# DA1469x register map
Vendor: Dialog; Series: DA1469x; File version: 1.2
CPU: CM33 r1p0, little endian, no MPU, FPU, 3 interrupt priority bits
Registers are 32-bit, read-write, reset 0x0 unless marked. A register's access mark holds for its fields unless they carry their own. Offsets are from the block's base; [hi:lo] are bit positions.

## CRG_SYS — CRG_SYS registers
Base 0x50040500
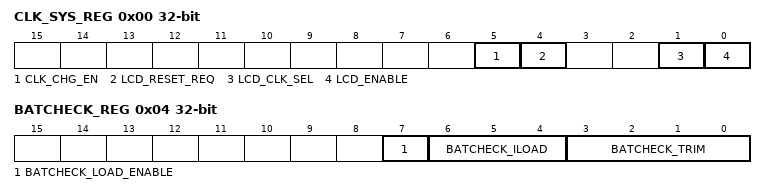
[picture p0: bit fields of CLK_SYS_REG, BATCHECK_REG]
0x00 CLK_SYS_REG — Peripheral divider register
  [5] CLK_CHG_EN — Enables the clocks for the charger FSM block
  [4] LCD_RESET_REQ — Generates a SW reset towards the LCD controller.
  [1] LCD_CLK_SEL — Selects the clock source 1 = DIV1 clock 0 = DIVN clock
  [0] LCD_ENABLE — Enables the clock
0x04 BATCHECK_REG
  [7] BATCHECK_LOAD_ENABLE — Enable a current load on the battery.
  [6:4] BATCHECK_ILOAD — Set the current load to (ILOAD+1) mA.
  [3:0] BATCHECK_TRIM — Trim the current load with steps of 2.7 percent from -19.1 percent to +19.1 percent. 0: +0.0 percent , 8: -0 percent 1: +2.7 percent , 9: -2.7 percent 2: +5.5 percent , 10: -5.5 percent 3: +8.2 percent , 11: -8.2 percent 4: +10.9 percent , 12: -10.9 percent 5: +13.6 percent , 13: -13.6 percent 6: +16.4 percent , 14: -16.4 percent 7: +19.1 percent , 15: -19.1 percent

## CRG_XTAL — CRG_XTAL registers
Base 0x50010000
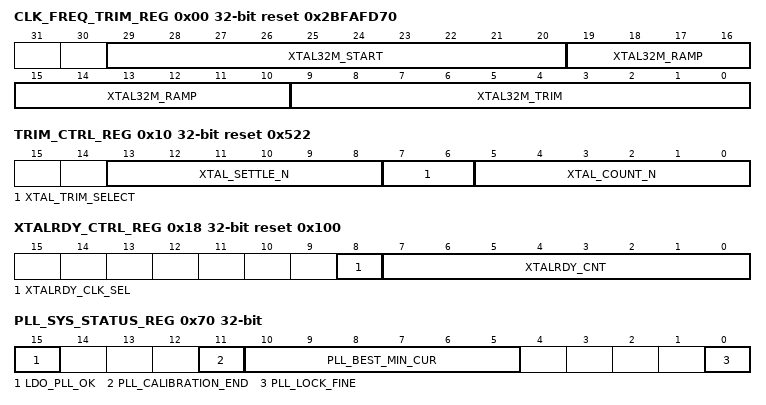
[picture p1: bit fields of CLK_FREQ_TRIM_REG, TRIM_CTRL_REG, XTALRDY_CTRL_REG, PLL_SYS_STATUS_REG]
0x00 CLK_FREQ_TRIM_REG reset 0x2BFAFD70 — Xtal frequency trimming register.
  [29:20] XTAL32M_START — Xtal frequency trimming register - START phase of startup 0x2BF = lowest frequency (high load capacitance) 0x000 = highest frequency (low load capacitance) Cload = 5.0p + 6.09p * XTAL32M_TRIM/0x2BF- this includes the PCB parasitic capacitances of the reference desing
  [19:10] XTAL32M_RAMP — Xtal frequency trimming register - RAMP phase of startup. 0x2BF = lowest frequency (high load capacitance) 0x000 = highest frequency (low load capacitance) Cload = 5.0p + 6.09p * XTAL32M_TRIM/0x2BF- this includes the PCB parasitic capacitances of the reference desing
  [9:0] XTAL32M_TRIM — Xtal frequency trimming register. 0x2BF = lowest frequency (high load capacitance) 0x000 = highest frequency (low load capacitance) Cload = 5.0p + 6.09p * XTAL32M_TRIM/0x2BF- this includes the PCB parasitic capacitances of the reference desing
0x10 TRIM_CTRL_REG reset 0x522 — Control trimming of the XTAL32M
  [13:8] XTAL_SETTLE_N — Designates that the XTAL can be safely used as the CPU clock. When XTAL_CLK_CNT reases this value, the signal XTAL_SETTLE_READY will be set
  [7:6] XTAL_TRIM_SELECT — Select which source controls the XTAL trimming 0b00: xtal counter. Starts CLK_FREQ_TRIM_REG[XTAL32M_START] after COUNT_N * 32 xtal pulses trim is changed to CLK_FREQ_TRIM_REG[XTAL32M_TRIM]. 0b01: xtal OK filter. Starts with CLK_FREQ_TRIM_REG[XTAL32M_START], when xtal is ramping is changed to CLK_FREQ_TRIM_REG[XTAL32M_TRIM]. 0b10: statically forced off. Only uses CLK_FREQ_TRIM_REG[XTAL32M_TRIM]. 0b11: xtal OK filter, 2 stage. Starts with CLK_FREQ_TRIM_REG[XTAL32M_START] switches to CLK_FREQ_TRIM_REG[XTAL32M_RAMP] after timeout (sw1='1', XTAL32M_CTRL0_REG[XTAL32M_SW_DELAY]), and switches to CLK_FREQ_TRIM_REG[XTAL32M_TRIM] when sw2='1'.
  [5:0] XTAL_COUNT_N — Defines the number of XTAL cycles to be counted, before the xtal trimming is applied, in steps of 32. 0x01: 32 0x02: 64 0x3f:2016
0x18 XTALRDY_CTRL_REG reset 0x100 — Control register for XTALRDY IRQ
  [8] XTALRDY_CLK_SEL — XTALRDY IRQ timer clock selection: 0: 32KHz 1: 256kHz
  [7:0] XTALRDY_CNT — Number of 32kHz or 256kHz cycles between the crystal is enabled, and the XTALRDY_IRQ is fired. Frequency set by XTALRDY_CLK_SEL. 0x00: no interrupt
0x70 PLL_SYS_STATUS_REG — System PLL status register.
  [15] LDO_PLL_OK ro — 1: Indicates that LDO PLL is in regulation.
  [11] PLL_CALIBRATION_END ro — Indicates that calibration has finished.
  [10:5] PLL_BEST_MIN_CUR ro — Calibrated VCO current.
  [0] PLL_LOCK_FINE ro — 1: PLL locked

## DW — DW registers
Base 0x30020000
0x00 AHB_DMA_PL1_REG reset 0xF — AHB-DMA layer priority level for RFTP (AHB DMA layer only)
  [3:0] AHB_DMA_PL1 — Arbitration priority for master RFPT. 0: lowest, 15: highest.
0x04 AHB_DMA_PL2_REG reset 0xE — AHB-DMA layer priority level for LCD (AHB DMA layer only)
  [3:0] AHB_DMA_PL2 — Arbitration priority for master LCD. 0: lowest, 15: highest.
0x08 AHB_DMA_PL3_REG reset 0xD — AHB-DMA layer Priority level for GEN-DMA (AHB DMA layer only)
  [3:0] AHB_DMA_PL3 — Arbitration priority for master GEN-DMA. 0: lowest, 15: highest.
0x0C AHB_DMA_PL4_REG reset 0xC — AHB-DMA layer Priority level for CRYPTO-DMA (AHB DMA layer only)
  [3:0] AHB_DMA_PL4 — Arbitration priority for master CRYPTO-DMA. 0: lowest, 15: highest.
0x48 AHB_DMA_DFLT_MASTER_REG — Default master ID number (AHB DMA layer only)
  [3:0] AHB_DMA_DFLT_MASTER — Default master ID number register. The default master is the master that is granted by the bus when no master has requested ownership. 0: Dummy master 1: RFPT 2: LCD 3: GEN-DMA 3: CRYPTO-DMA
0x4C AHB_DMA_WTEN_REG — Weighted-Token Arbitration Scheme Enable (AHB DMA layer only)
  [0] AHB_DMA_WTEN — Weighted-token arbitration scheme enable.
0x50 AHB_DMA_TCL_REG reset 0xFFFF — Master clock refresh period (AHB DMA layer only)
  [15:0] AHB_DMA_TCL — Master clock refresh period, counting clock cycles. An arbitration period is defined over this number of tokens. When a new arbitration period starts, the master counters are reloaded. Recommended value is the sum of the AHB_DMA_CCLMx_REG valuesplus 2 tokens for each master, i.e. plus 6.
0x54 AHB_DMA_CCLM1_REG reset 0xF — USB Master clock tokens (AHB DMA layer only)
  [15:0] AHB_DMA_CCLM — Number of tokens (counted in AHB clock cycles) that a master can use on the bus before it has to arbitrate on a bus master with low priority and having tokens. Masters with tokens remaining have priority over masters that have used all of their tokens. User should configure all the token values ensuring that the sum does not exceeds the total allocated number of tokens. If a value of zero is configured, then the bus is deemed to have infinite tokens and will always operate in the upper-tier of arbitration.
0x58 AHB_DMA_CCLM2_REG reset 0xF — GenDMA Master clock tokens (AHB DMA layer only)
  [15:0] AHB_DMA_CCLM — Refer to AHB_DMA_CCLM1_REG
0x5C AHB_DMA_CCLM3_REG reset 0xF — CRYPTO Master clock tokens (AHB DMA layer only)
  [15:0] AHB_DMA_CCLM — AHB_DMA_CCLM1_REG
0x60 AHB_DMA_CCLM4_REG reset 0xF — CRYPTO Master clock tokens (AHB DMA layer only)
  [15:0] AHB_DMA_CCLM — AHB_DMA_CCLM1_REG
0x90 AHB_DMA_VERSION_REG reset 0x3231332A (reset mask 0x7FFFFFFF) — Version ID (AHB DMA layer only)
  [31:0] AHB_DMA_VERSION ro
